# STM32N657 register map
File version: 1.0
CPU: CM55 r0p1, little endian, no MPU, FPU, vendor SysTick, 8 interrupt priority bits
Registers are 32-bit, read-write, reset 0x0 unless marked. A register's access mark holds for its fields unless they carry their own. Offsets are from the block's base; [hi:lo] are bit positions.

## TIM9 — General-purpose timers
Base 0x42004C00
Same registers: TIM9_S 0x52004C00
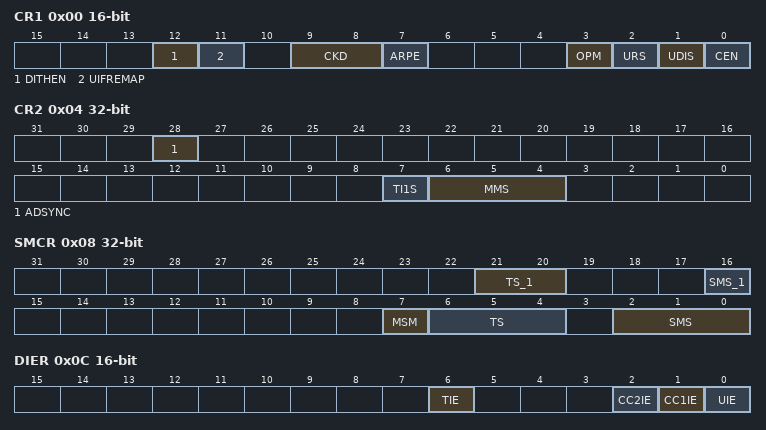
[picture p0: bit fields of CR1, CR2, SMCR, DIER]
0x00 CR1 16-bit — TIM9 control register 1
  [12] DITHEN — Dithering enable
  [11] UIFREMAP — UIF status bit remapping
  [9:8] CKD — Clock division
  [7] ARPE — Auto-reload preload enable
  [3] OPM — One-pulse mode
  [2] URS — Update request source
  [1] UDIS — Update disable
  [0] CEN — Counter enable
0x04 CR2 — TIM12 control register 2
  [28] ADSYNC — ADC synchronization
  [7] TI1S — tim_ti1 selection
  [6:4] MMS — Master mode selection
0x08 SMCR — TIM9 slave mode control register
  [21:20] TS_1 — TS[4:3]
  [16] SMS_1 — SMS[3]
  [7] MSM — Master/Slave mode
  [6:4] TS — TS[0]: Trigger selection
  [2:0] SMS — SMS[0]: Slave mode selection
0x0C DIER 16-bit — TIM9 Interrupt enable register
  [6] TIE — Trigger interrupt enable
  [2] CC2IE — Capture/Compare 2 interrupt enable
  [1] CC1IE — Capture/Compare 1 interrupt enable
  [0] UIE — Update interrupt enable
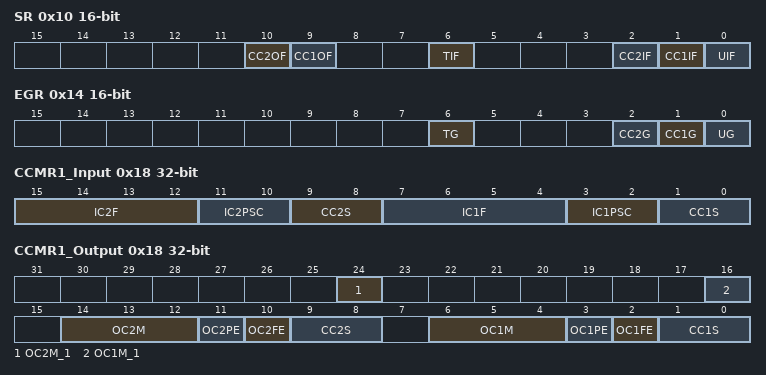
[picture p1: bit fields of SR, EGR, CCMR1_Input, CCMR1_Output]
0x10 SR 16-bit — TIM9 status register
  [10] CC2OF — Capture/compare 2 overcapture flag
  [9] CC1OF — Capture/Compare 1 overcapture flag
  [6] TIF — Trigger interrupt flag
  [2] CC2IF — Capture/Compare 2 interrupt flag
  [1] CC1IF — Capture/compare 1 interrupt flag
  [0] UIF — Update interrupt flag
0x14 EGR 16-bit wo — TIM9 event generation register
  [6] TG — Trigger generation
  [2] CC2G — Capture/compare 2 generation
  [1] CC1G — Capture/compare 1 generation
  [0] UG — Update generation
0x18 CCMR1_Input — TIM9 capture/compare mode register 1 [alternate]
  [15:12] IC2F — Input capture 2 filter
  [11:10] IC2PSC — Input capture 2 prescaler
  [9:8] CC2S — Capture/compare 2 selection
  [7:4] IC1F — Input capture 1 filter
  [3:2] IC1PSC — Input capture 1 prescaler
  [1:0] CC1S — Capture/Compare 1 selection
0x18 CCMR1_Output (alternate view of CCMR1_Input) — TIM9 capture/compare mode register 1 [alternate]
  [24] OC2M_1 — OC2M[3]
  [16] OC1M_1 — OC1M[3]
  [14:12] OC2M — OC2M[2:0]: Output compare 2 mode
  [11] OC2PE — Output compare 2 preload enable
  [10] OC2FE — Output compare 2 fast enable
  [9:8] CC2S — Capture/Compare 2 selection
  [6:4] OC1M — OC1M[2:0]: Output compare 1 mode (refer to bit 16 for OC1M[3])
  [3] OC1PE — Output compare 1 preload enable
  [2] OC1FE — Output compare 1 fast enable
  [1:0] CC1S — Capture/Compare 1 selection
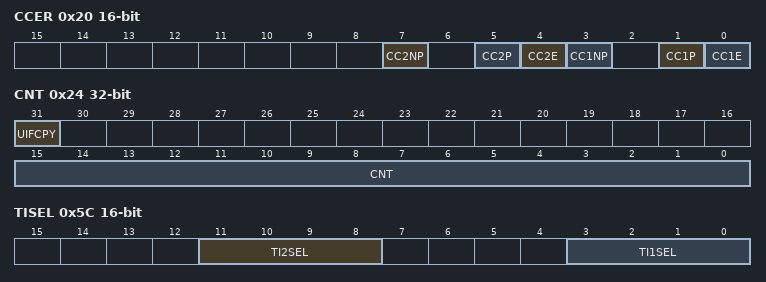
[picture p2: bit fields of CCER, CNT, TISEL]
0x20 CCER 16-bit — TIM9 capture/compare enable register
  [7] CC2NP — Capture/Compare 2 output Polarity
  [5] CC2P — Capture/Compare 2 output Polarity
  [4] CC2E — Capture/Compare 2 output enable
  [3] CC1NP — Capture/Compare 1 complementary output Polarity
  [1] CC1P — Capture/Compare 1 output Polarity.
  [0] CC1E — Capture/Compare 1 output enable.
0x24 CNT — TIM9 counter
  [31] UIFCPY — UIF Copy
  [15:0] CNT — Counter value
0x28 PSC 16-bit — TIM9 prescaler
  [15:0] PSC — Prescaler value
0x2C ARR reset 0xFFFF — TIM9 auto-reload register
  [19:0] ARR — Auto-reload value
0x34 CCR1 — TIM9 capture/compare register 1
  [19:0] CCR1 — Capture/compare 1 value
0x38 CCR2 — TIM9 capture/compare register 2
  [19:0] CCR2 — Capture/compare 2 value
0x5C TISEL 16-bit — TIM9 timer input selection register
  [11:8] TI2SEL — selects tim_ti2_in[15:0] input
  [3:0] TI1SEL — selects tim_ti1_in[15:0] input

## TIM12 — General-purpose timers
Base 0x40001800
Same registers: TIM12_S 0x50001800
Registers as TIM9 (with TIM9 read as TIM12); these are added or differ:
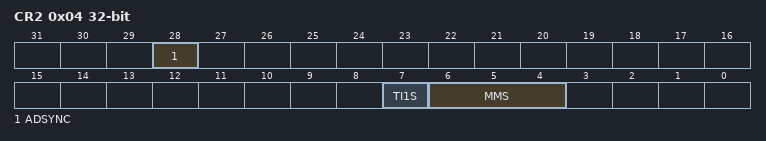
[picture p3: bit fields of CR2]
0x04 CR2 — TIM12 control register 2
  [28] ADSYNC — ADC synchronization
  [7] TI1S — tim_ti1 selection
  [6:4] MMS — Master mode selection

## TIM10 — General-purpose timers
Base 0x40003000
Same registers: TIM10_S 0x50003000
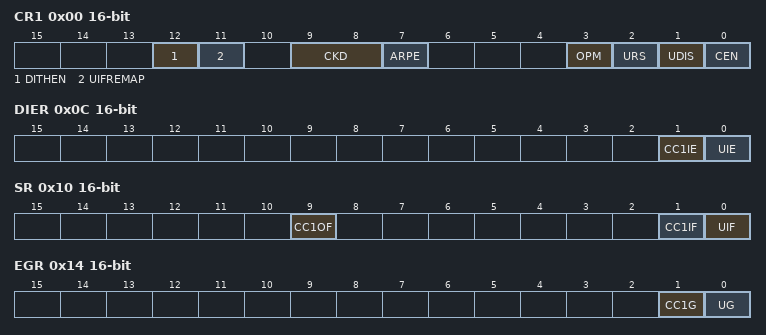
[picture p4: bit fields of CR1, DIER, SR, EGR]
0x00 CR1 16-bit — TIM10 control register 1
  [12] DITHEN — Dithering enable
  [11] UIFREMAP — UIF status bit remapping
  [9:8] CKD — Clock division
  [7] ARPE — Auto-reload preload enable
  [3] OPM — One-pulse mode
  [2] URS — Update request source
  [1] UDIS — Update disable
  [0] CEN — Counter enable
0x0C DIER 16-bit — TIM10 Interrupt enable register
  [1] CC1IE — Capture/Compare 1 interrupt enable
  [0] UIE — Update interrupt enable
0x10 SR 16-bit — TIM10 status register
  [9] CC1OF — Capture/Compare 1 overcapture flag
  [1] CC1IF — Capture/compare 1 interrupt flag
  [0] UIF — Update interrupt flag
0x14 EGR 16-bit wo — TIM10 event generation register
  [1] CC1G — Capture/compare 1 generation
  [0] UG — Update generation
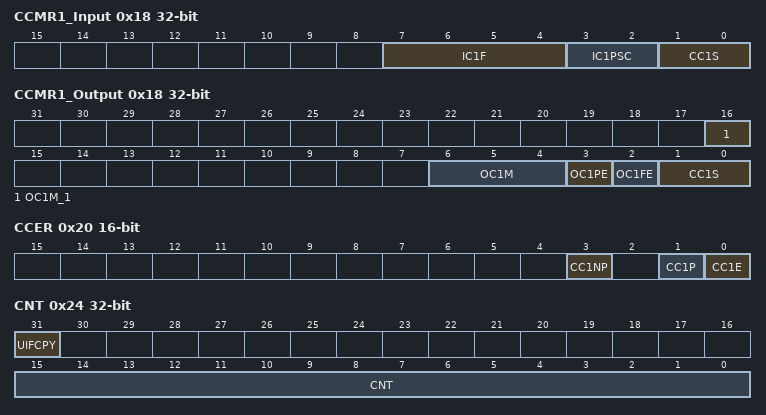
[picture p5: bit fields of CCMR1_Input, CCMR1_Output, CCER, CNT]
0x18 CCMR1_Input — TIM10 capture/compare mode register 1
  [7:4] IC1F — Input capture 1 filter
  [3:2] IC1PSC — Input capture 1 prescaler
  [1:0] CC1S — Capture/Compare 1 selection
0x18 CCMR1_Output (alternate view of CCMR1_Input) — TIM10 capture/compare mode register 1 [alternate]
  [16] OC1M_1 — OC1M[3]
  [6:4] OC1M — OC1M[2:0]: Output compare 1 mode (refer to bit 16 for OC1M[3])
  [3] OC1PE — Output compare 1 preload enable
  [2] OC1FE — Output compare 1 fast enable
  [1:0] CC1S — Capture/Compare 1 selection
0x20 CCER 16-bit — TIM10 capture/compare enable register
  [3] CC1NP — Capture/Compare 1 complementary output Polarity.
  [1] CC1P — Capture/Compare 1 output Polarity.
  [0] CC1E — Capture/Compare 1 output enable.
0x24 CNT — TIM10 counter
  [31] UIFCPY — UIF Copy
  [15:0] CNT — Counter value
0x28 PSC 16-bit — TIM10 prescaler
  [15:0] PSC — Prescaler value
0x2C ARR reset 0xFFFF — TIM10 auto-reload register
  [19:0] ARR — Auto-reload value
0x34 CCR1 — TIM10 capture/compare register 1
  [19:0] CCR1 — Capture/compare 1 value
0x5C TISEL 16-bit — TIM10 timer input selection register
  [3:0] TI1SEL — selects tim_ti1_in[15:0] input

## TIM11 — General-purpose timers
Base 0x40003400
Same registers: TIM11_S 0x50003400
Registers as TIM10 (with TIM10 read as TIM11).

## TIM13 — General-purpose timers
Base 0x40001C00
Same registers: TIM13_S 0x50001C00
Registers as TIM10 (with TIM10 read as TIM13).

## TIM14 — General-purpose timers
Base 0x40002000
Same registers: TIM14_S 0x50002000
Registers as TIM10 (with TIM10 read as TIM14).

## VREFBUF — Voltage reference buffer
Base 0x46003C00
Same registers: VREFBUF_S 0x56003C00
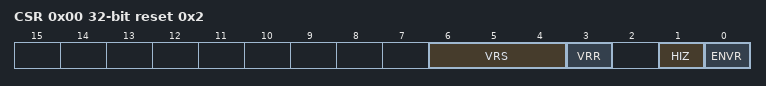
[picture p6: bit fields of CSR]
0x00 CSR access per field reset 0x2 — VREFBUF control and status register
  [6:4] VRS rw — Voltage reference scale
  [3] VRR ro — Voltage reference buffer ready
  [1] HIZ rw — High impedance mode
  [0] ENVR rw — Voltage reference buffer mode enable
0x04 CCR (reset mask 0xFFFFFF00) — VREFBUF calibration control register
  [5:0] TRIM — Trimming code

## WWDG — System window watchdog
Base 0x40002C00
Same registers: WWDG_S 0x50002C00
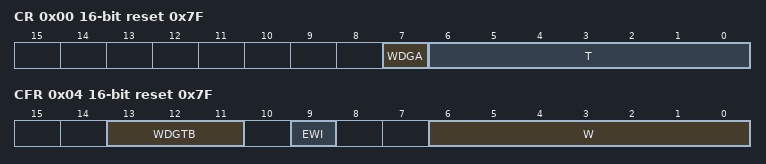
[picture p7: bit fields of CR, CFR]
0x00 CR 16-bit reset 0x7F — WWDG control register
  [7] WDGA — Activation bit
    0=Disabled (Watchdog disabled); 1=Enabled (Watchdog enabled)
  [6:0] T — 7-bit counter (MSB to LSB)
0x04 CFR 16-bit access not given reset 0x7F — WWDG configuration register
  [13:11] WDGTB — Timer base
    0=Div1 (Counter clock (PCLK1 div 4096) div 1); 1=Div2 (Counter clock (PCLK1 div 4096) div 2); 2=Div4 (Counter clock (PCLK1 div 4096) div 4); 3=Div8 (Counter clock (PCLK1 div 4096) div 8); 4=Div16 (Counter clock (PCLK1 div 4096) div 16); 5=Div32 (Counter clock (PCLK1 div 4096) div 32); 6=Div64 (Counter clock (PCLK1 div 4096) div 64); 7=Div128 (Counter clock (PCLK1 div 4096) div 128)
  [9] EWI rw — Early wakeup interrupt
    on write: 1=Enable (interrupt occurs whenever the counter reaches the value 0x40)
  [6:0] W rw — 7-bit window value
0x08 SR 16-bit — WWDG status register
  [0] EWIF write-0-clears — Early wakeup interrupt flag
    on read: 0=Finished (The EWI Interrupt Service Routine has been serviced); 1=Pending (The EWI Interrupt Service Routine has been triggered) | on write: 0=Finished (The EWI Interrupt Service Routine has been serviced)

## XSPIM — XSPI I/O manager
Base 0x4802B400
Same registers: XSPIM_S 0x5802B400
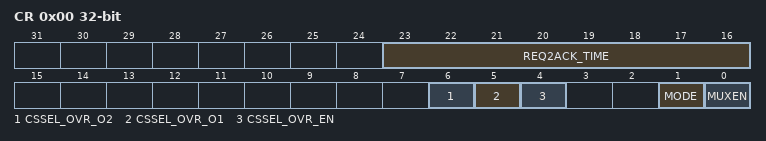
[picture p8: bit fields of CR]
0x00 CR — XSPIM control register
  [23:16] REQ2ACK_TIME — REQ to ACK time
  [6] CSSEL_OVR_O2 — Chip select selector override setting for XSPI2
  [5] CSSEL_OVR_O1 — Chip select selector override setting for XSPI1
  [4] CSSEL_OVR_EN — Chip select selector override enable
  [1] MODE — XSPI multiplexing mode
  [0] MUXEN — Multiplexed mode enable
